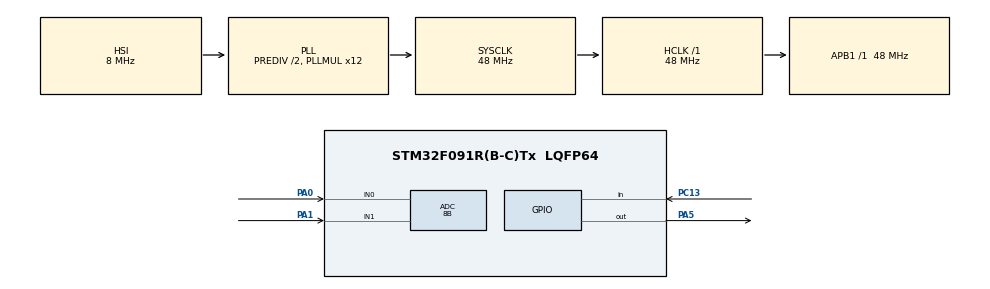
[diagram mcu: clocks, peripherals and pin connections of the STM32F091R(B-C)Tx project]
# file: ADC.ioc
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ADC.Resolution=ADC_RESOLUTION_8B
ADC.SamplingTime=ADC_SAMPLETIME_28CYCLES_5
Mcu.Family=STM32F0
Mcu.Name=STM32F091R(B-C)Tx
Mcu.Package=LQFP64
PA0.Mode=IN0
PA0.Signal=ADC_IN0
PA1.Mode=IN1
PA1.Signal=ADC_IN1
PA5.Signal=GPIO_Output
PC13.Signal=GPIO_Input
ProjectManager.HeapSize=0x200
ProjectManager.StackSize=0x400
ProjectManager.TargetToolchain=MDK-ARM V5
RCC.AHBFreq_Value=48000000
RCC.APB1Freq_Value=48000000
RCC.APB1TimFreq_Value=48000000
RCC.FLatency-AdvancedSettings=FLASH_LATENCY_1
RCC.HCLKFreq_Value=48000000
RCC.PLLDivider=RCC_PREDIV_DIV2
RCC.PLLMUL=RCC_PLL_MUL12
RCC.PREFETCH_ENABLE-AdvancedSettings=1
RCC.SYSCLKFreq_VALUE=48000000
RCC.SYSCLKSource=RCC_SYSCLKSOURCE_PLLCLK
board=NUCLEO-F091RC

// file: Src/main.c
/**
  ******************************************************************************
  * @file           : main.c
  * @brief          : Main program body
  ******************************************************************************
  ** This notice applies to any and all portions of this file
  * that are not between comment pairs USER CODE BEGIN and
  * USER CODE END. Other portions of this file, whether
  * inserted by the user or by software development tools
  * are owned by their respective copyright owners.
  *
  * COPYRIGHT(c) 2018 STMicroelectronics
  *
  * Redistribution and use in source and binary forms, with or without modification,
  * are permitted provided that the following conditions are met:
  *   1. Redistributions of source code must retain the above copyright notice,
  *      this list of conditions and the following disclaimer.
  *   2. Redistributions in binary form must reproduce the above copyright notice,
  *      this list of conditions and the following disclaimer in the documentation
  *      and/or other materials provided with the distribution.
  *   3. Neither the name of STMicroelectronics nor the names of its contributors
  *      may be used to endorse or promote products derived from this software
  *      without specific prior written permission.
  *
  * THIS SOFTWARE IS PROVIDED BY THE COPYRIGHT HOLDERS AND CONTRIBUTORS "AS IS"
  * AND ANY EXPRESS OR IMPLIED WARRANTIES, INCLUDING, BUT NOT LIMITED TO, THE
  * IMPLIED WARRANTIES OF MERCHANTABILITY AND FITNESS FOR A PARTICULAR PURPOSE ARE
  * DISCLAIMED. IN NO EVENT SHALL THE COPYRIGHT HOLDER OR CONTRIBUTORS BE LIABLE
  * FOR ANY DIRECT, INDIRECT, INCIDENTAL, SPECIAL, EXEMPLARY, OR CONSEQUENTIAL
  * DAMAGES (INCLUDING, BUT NOT LIMITED TO, PROCUREMENT OF SUBSTITUTE GOODS OR
  * SERVICES; LOSS OF USE, DATA, OR PROFITS; OR BUSINESS INTERRUPTION) HOWEVER
  * CAUSED AND ON ANY THEORY OF LIABILITY, WHETHER IN CONTRACT, STRICT LIABILITY,
  * OR TORT (INCLUDING NEGLIGENCE OR OTHERWISE) ARISING IN ANY WAY OUT OF THE USE
  * OF THIS SOFTWARE, EVEN IF ADVISED OF THE POSSIBILITY OF SUCH DAMAGE.
  *
  ******************************************************************************
  */
#include "main.h"
#include "stm32f0xx_hal.h"

ADC_HandleTypeDef hadc;

/* USER CODE BEGIN PV */
/* Private variables ---------------------------------------------------------*/

/* USER CODE END PV */

void SystemClock_Config(void);
static void MX_GPIO_Init(void);
static void MX_ADC_Init(void);

/* USER CODE BEGIN PFP */
/* Private function prototypes -----------------------------------------------*/

/* USER CODE END PFP */

/* USER CODE BEGIN 0 */
uint32_t adcVal0, adcVal1;
/* USER CODE END 0 */

int main(void)
{

  /* MCU Configuration----------------------------------------------------------*/

  /* Reset of all peripherals, Initializes the Flash interface and the Systick. */
  HAL_Init();

  /* Configure the system clock */
  SystemClock_Config();

  /* Initialize all configured peripherals */
  MX_GPIO_Init();
  MX_ADC_Init();

  /* Infinite loop */
  while (1)
  {

  /* USER CODE BEGIN 3 */
		HAL_ADC_Start(&hadc);
		if(HAL_ADC_PollForConversion(&hadc, 5) == HAL_OK)
		{
			adcVal0 = HAL_ADC_GetValue(&hadc);
		}
		HAL_Delay(50);
  }
  /* USER CODE END 3 */

}

void SystemClock_Config(void)
{

  RCC_OscInitTypeDef RCC_OscInitStruct;
  RCC_ClkInitTypeDef RCC_ClkInitStruct;

    /**Initializes the CPU, AHB and APB busses clocks
    */
  RCC_OscInitStruct.OscillatorType = RCC_OSCILLATORTYPE_HSI|RCC_OSCILLATORTYPE_HSI14;
  RCC_OscInitStruct.HSIState = RCC_HSI_ON;
  RCC_OscInitStruct.HSI14State = RCC_HSI14_ON;
  RCC_OscInitStruct.HSICalibrationValue = 16;
  RCC_OscInitStruct.HSI14CalibrationValue = 16;
  RCC_OscInitStruct.PLL.PLLState = RCC_PLL_ON;
  RCC_OscInitStruct.PLL.PLLSource = RCC_PLLSOURCE_HSI;
  RCC_OscInitStruct.PLL.PLLMUL = RCC_PLL_MUL12;
  RCC_OscInitStruct.PLL.PREDIV = RCC_PREDIV_DIV2;
  if (HAL_RCC_OscConfig(&RCC_OscInitStruct) != HAL_OK)
  {
    _Error_Handler(__FILE__, __LINE__);
  }

    /**Initializes the CPU, AHB and APB busses clocks
    */
  RCC_ClkInitStruct.ClockType = RCC_CLOCKTYPE_HCLK|RCC_CLOCKTYPE_SYSCLK
                              |RCC_CLOCKTYPE_PCLK1;
  RCC_ClkInitStruct.SYSCLKSource = RCC_SYSCLKSOURCE_PLLCLK;
  RCC_ClkInitStruct.AHBCLKDivider = RCC_SYSCLK_DIV1;
  RCC_ClkInitStruct.APB1CLKDivider = RCC_HCLK_DIV1;

  if (HAL_RCC_ClockConfig(&RCC_ClkInitStruct, FLASH_LATENCY_1) != HAL_OK)
  {
    _Error_Handler(__FILE__, __LINE__);
  }

    /**Configure the Systick interrupt time
    */
  HAL_SYSTICK_Config(HAL_RCC_GetHCLKFreq()/1000);

    /**Configure the Systick
    */
  HAL_SYSTICK_CLKSourceConfig(SYSTICK_CLKSOURCE_HCLK);

  /* SysTick_IRQn interrupt configuration */
  HAL_NVIC_SetPriority(SysTick_IRQn, 0, 0);
}

/* ADC init function */
static void MX_ADC_Init(void)
{

  ADC_ChannelConfTypeDef sConfig;

    /**Configure the global features of the ADC (Clock, Resolution, Data Alignment and number of conversion)
    */
  hadc.Instance = ADC1;
  hadc.Init.ClockPrescaler = ADC_CLOCK_ASYNC_DIV1;
  hadc.Init.Resolution = ADC_RESOLUTION_8B;
  hadc.Init.DataAlign = ADC_DATAALIGN_RIGHT;
  hadc.Init.ScanConvMode = ADC_SCAN_DIRECTION_FORWARD;
  hadc.Init.EOCSelection = ADC_EOC_SINGLE_CONV;
  hadc.Init.LowPowerAutoWait = DISABLE;
  hadc.Init.LowPowerAutoPowerOff = DISABLE;
  hadc.Init.ContinuousConvMode = DISABLE;
  hadc.Init.DiscontinuousConvMode = DISABLE;
  hadc.Init.ExternalTrigConv = ADC_SOFTWARE_START;
  hadc.Init.ExternalTrigConvEdge = ADC_EXTERNALTRIGCONVEDGE_NONE;
  hadc.Init.DMAContinuousRequests = DISABLE;
  hadc.Init.Overrun = ADC_OVR_DATA_PRESERVED;
  if (HAL_ADC_Init(&hadc) != HAL_OK)
  {
    _Error_Handler(__FILE__, __LINE__);
  }

    /**Configure for the selected ADC regular channel to be converted.
    */
  sConfig.Channel = ADC_CHANNEL_0;
  sConfig.Rank = ADC_RANK_CHANNEL_NUMBER;
  sConfig.SamplingTime = ADC_SAMPLETIME_28CYCLES_5;
  if (HAL_ADC_ConfigChannel(&hadc, &sConfig) != HAL_OK)
  {
    _Error_Handler(__FILE__, __LINE__);
  }

    /**Configure for the selected ADC regular channel to be converted.
    */
  sConfig.Channel = ADC_CHANNEL_1;
  if (HAL_ADC_ConfigChannel(&hadc, &sConfig) != HAL_OK)
  {
    _Error_Handler(__FILE__, __LINE__);
  }

}

/** Configure pins as
        * Analog
        * Input
        * Output
        * EVENT_OUT
        * EXTI
*/
static void MX_GPIO_Init(void)
{

  GPIO_InitTypeDef GPIO_InitStruct;

  /* GPIO Ports Clock Enable */
  __HAL_RCC_GPIOC_CLK_ENABLE();
  __HAL_RCC_GPIOA_CLK_ENABLE();

  /*Configure GPIO pin Output Level */
  HAL_GPIO_WritePin(GPIOA, GPIO_PIN_5, GPIO_PIN_RESET);

  /*Configure GPIO pin : PC13 */
  GPIO_InitStruct.Pin = GPIO_PIN_13;
  GPIO_InitStruct.Mode = GPIO_MODE_INPUT;
  GPIO_InitStruct.Pull = GPIO_NOPULL;
  HAL_GPIO_Init(GPIOC, &GPIO_InitStruct);

  /*Configure GPIO pin : PA5 */
  GPIO_InitStruct.Pin = GPIO_PIN_5;
  GPIO_InitStruct.Mode = GPIO_MODE_OUTPUT_PP;
  GPIO_InitStruct.Pull = GPIO_NOPULL;
  GPIO_InitStruct.Speed = GPIO_SPEED_FREQ_LOW;
  HAL_GPIO_Init(GPIOA, &GPIO_InitStruct);

}

void _Error_Handler(char *file, int line)
{
  while(1)
  {
  }
}

/************************ (C) COPYRIGHT STMicroelectronics *****END OF FILE****/
